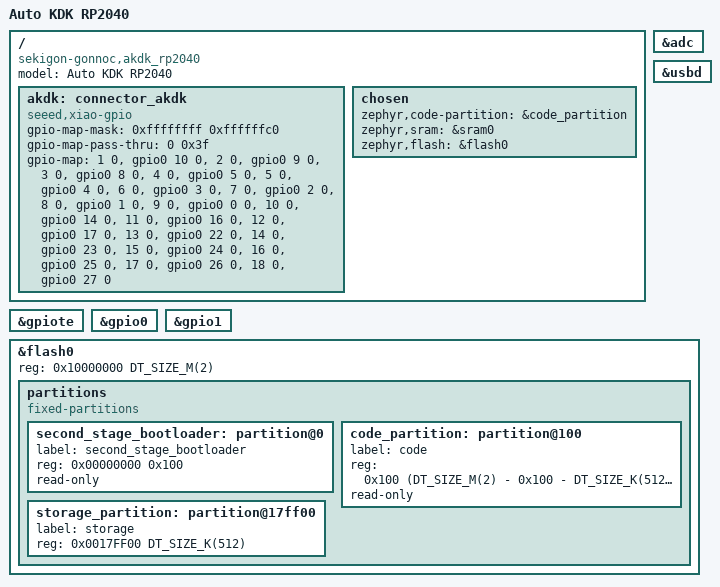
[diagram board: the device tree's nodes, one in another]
/dts-v1/;
#include <rpi_pico/rp2040.dtsi>

/ {
     model = "Auto KDK RP2040";
     compatible = "sekigon-gonnoc,akdk_rp2040";

	akdk: connector_akdk {
		compatible = "seeed,xiao-gpio";
		#gpio-cells = <2>;
		gpio-map-mask = <0xffffffff 0xffffffc0>;
		gpio-map-pass-thru = <0 0x3f>;
		gpio-map
			= <1 0 &gpio0 10 0>
			, <2 0 &gpio0 9 0>
			, <3 0 &gpio0 8 0>
			, <4 0 &gpio0 5 0>
			, <5 0 &gpio0 4 0>
			, <6 0 &gpio0 3 0>
			, <7 0 &gpio0 2 0>
			, <8 0 &gpio0 1 0>
			, <9 0 &gpio0 0 0>
			, <10 0 &gpio0 14 0>
			, <11 0 &gpio0 16 0>
			, <12 0 &gpio0 17 0>
			, <13 0 &gpio0 22 0>
			, <14 0 &gpio0 23 0>
			, <15 0 &gpio0 24 0>
			, <16 0 &gpio0 25 0>
			, <17 0 &gpio0 26 0>
			, <18 0 &gpio0 27 0>
		;
	};

     chosen {
        zephyr,code-partition = &code_partition;
        zephyr,sram = &sram0;
        zephyr,flash = &flash0;
     };
};

&adc {
	status = "okay";
};

&gpiote {
	status = "okay";
};

&gpio0 {
	status = "okay";
};

&gpio1 {
	status = "okay";
};

zephyr_udc0: &usbd {
	status = "okay";
};

&flash0 {
    /* 2MB of flash minus the 0x100 used for
     * the second stage bootloader
     */
    reg = <0x10000000 DT_SIZE_M(2)>;

    partitions {
        compatible = "fixed-partitions";
        #address-cells = <1>;
        #size-cells = <1>;

        /* Reserved memory for the second stage bootloader */
        second_stage_bootloader: partition@0 {
            label = "second_stage_bootloader";
            reg = <0x00000000 0x100>;
            read-only;
        };

        /*
         * Start at the beginning of usable flash.
         * 1.5MiB minus reserved memory for bootloader
         */
        code_partition: partition@100 {
            label = "code";
            reg = <0x100 (DT_SIZE_M(2) - 0x100 - DT_SIZE_K(512))>;
            read-only;
        };

        /*
         * The final 512 KiB is reserved for the application.
         * Storage partition may be used by FCB/LittleFS/NVS.
         */
        storage_partition: partition@17ff00 {
            label = "storage";
            reg = <0x0017FF00 DT_SIZE_K(512)>;
        };
    };
};

